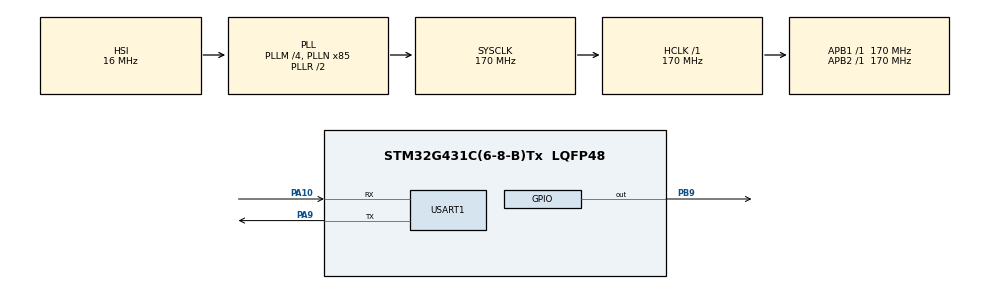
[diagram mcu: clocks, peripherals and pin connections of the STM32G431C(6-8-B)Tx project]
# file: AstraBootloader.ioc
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Mcu.Family=STM32G4
Mcu.Name=STM32G431C(6-8-B)Tx
Mcu.Package=LQFP48
NVIC.PriorityGroup=NVIC_PRIORITYGROUP_4
NVIC.USART1_IRQn=true\:2\:0\:false\:false\:true\:true\:true\:true
PA10.Mode=Asynchronous
PA10.Signal=USART1_RX
PA9.Mode=Asynchronous
PA9.Signal=USART1_TX
PB9.Signal=GPIO_Output
PC14-OSC32_IN.Mode=LSE-External-Oscillator
PC14-OSC32_IN.Signal=RCC_OSC32_IN
PC15-OSC32_OUT.Mode=LSE-External-Oscillator
PC15-OSC32_OUT.Signal=RCC_OSC32_OUT
PF0-OSC_IN.Mode=HSE-External-Oscillator
PF0-OSC_IN.Signal=RCC_OSC_IN
PF1-OSC_OUT.Mode=HSE-External-Oscillator
PF1-OSC_OUT.Signal=RCC_OSC_OUT
ProjectManager.HeapSize=0x200
ProjectManager.StackSize=0x400
ProjectManager.TargetToolchain=CMake
RCC.ADC12Freq_Value=170000000
RCC.AHBFreq_Value=170000000
RCC.APB1Freq_Value=170000000
RCC.APB1TimFreq_Value=170000000
RCC.APB2Freq_Value=170000000
RCC.APB2TimFreq_Value=170000000
RCC.CortexFreq_Value=170000000
RCC.EXTERNAL_CLOCK_VALUE=12288000
RCC.HCLKFreq_Value=170000000
RCC.HSE_VALUE=8000000
RCC.HSI48_VALUE=48000000
RCC.HSI_VALUE=16000000
RCC.PLLM=RCC_PLLM_DIV4
RCC.PLLN=85
RCC.SYSCLKFreq_VALUE=170000000
RCC.SYSCLKSource=RCC_SYSCLKSOURCE_PLLCLK
RCC.USBFreq_Value=170000000
RCC.VCOOutputFreq_Value=340000000
USART1.VirtualMode-Asynchronous=VM_ASYNC
VP_SYS_VS_DBSignals.Mode=DisableDeadBatterySignals
board=custom

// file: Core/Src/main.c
/* USER CODE BEGIN Header */
/**
  ******************************************************************************
  * @file           : main.c
  * @brief          : Main program body
  ******************************************************************************
  * @attention
  *
  * Copyright (c) 2026 STMicroelectronics.
  * All rights reserved.
  *
  * This software is licensed under terms that can be found in the LICENSE file
  * in the root directory of this software component.
  * If no LICENSE file comes with this software, it is provided AS-IS.
  *
  ******************************************************************************
  */
/* USER CODE END Header */
#include "main.h"

/* USER CODE BEGIN Includes */
#include "FlashLayout.h"
#include "stm32g4xx_hal.h"
#include "stm32g4xx_hal_gpio.h"
#include "bootloaderJump.h"
#include "AppHeader.h"
#include "OtaRequest.h"
#include "OtaStream.h"
#include "OtaEngine.h"
#include "OtaStreamUart.h"
#include "BootloaderStateMachine.h"
/* USER CODE END Includes */

/* USER CODE BEGIN PD */

/* Budget for the 20-byte header once the device has announced itself. */
#define OTA_HEADER_TIMEOUT_MS 5000U

/* Budget per stored Flash page, counted between two received chunks. */
#define OTA_PAGE_TIMEOUT_MS 5000U

/* USER CODE END PD */

UART_HandleTypeDef huart1;

/* USER CODE BEGIN PV */

static UartCtx_t otaCtx;

/* USER CODE END PV */

void SystemClock_Config(void);
static void MX_GPIO_Init(void);
static void MX_USART1_UART_Init(void);
/* USER CODE BEGIN PFP */
static void RunOtaUpdate(void);
static void OtaOnPageStored(uint32_t chunkBytes, bool isLast, void *userData);
/* USER CODE END PFP */

/* USER CODE BEGIN 0 */

static void OtaOnPageStored(uint32_t chunkBytes, bool isLast, void *userData)
{
	(void)userData;

	BootloaderSMDispatch(EVENT_DATA_PACKET_RCVD, &chunkBytes);

	if (isLast != false)
	{
		BootloaderSMDispatch(EVENT_LAST_PACKET_RCVD, NULL);
	}
}

static void RunOtaUpdate(void)
{
	OtaStream_t stream;
	AppHeader_t header;

	OtaStreamUartInit(&stream, &otaCtx, &huart1);

	if (OtaStreamUartAnnounce(&otaCtx) != 0)
	{
		BootloaderSMDispatch(EVENT_HARDWARE_ERROR, NULL);
		return;
	}

	BootloaderSMDispatch(EVENT_CONN_ESTABLISHED, NULL);

	if (OtaReadHeader(&stream, &header, OTA_HEADER_TIMEOUT_MS) != OTA_OK)
	{
		BootloaderSMDispatch(EVENT_TIMEOUT, NULL);
		return;
	}

	BootloaderSMDispatch(EVENT_SIZE_RECEIVED, &header.size);

	HAL_GPIO_WritePin(GPIOB, GPIO_PIN_9, GPIO_PIN_SET);

	if (OtaEraseAppSlot(&stream, APP_START_ADDR, header.size) != OTA_OK)
	{
		BootloaderSMDispatch(EVENT_HARDWARE_ERROR, NULL);
		return;
	}

	BootloaderSMDispatch(EVENT_ERASE_DONE, NULL);

	if (OtaReceiveImage(&stream, APP_START_ADDR, header.size, OTA_PAGE_TIMEOUT_MS,
	                    OtaOnPageStored, NULL) != OTA_OK)
	{
		BootloaderSMDispatch(EVENT_CANCEL, NULL);
		return;
	}

	if (OtaVerifyImage(&stream, APP_START_ADDR, header.size, header.crc) != OTA_OK)
	{
		BootloaderSMDispatch(EVENT_CHECKSUM_ERROR, NULL);
		return;
	}

	BootloaderSMDispatch(EVENT_CHECKSUM_OK, NULL);

	if (OtaRequestCommitHeader(&header) == false)
	{
		BootloaderSMDispatch(EVENT_HARDWARE_ERROR, NULL);
		return;
	}

	BootloaderSMDispatch(EVENT_UPDATE_SUCCESS, NULL);

	HAL_GPIO_WritePin(GPIOB, GPIO_PIN_9, GPIO_PIN_RESET);
}

/* USER CODE END 0 */

int main(void)
{

	/* MCU Configuration--------------------------------------------------------*/

	/* Reset of all peripherals, Initializes the Flash interface and the Systick. */
	HAL_Init();

	/* Configure the system clock */
	SystemClock_Config();

	/* Initialize all configured peripherals */
	MX_GPIO_Init();
	MX_USART1_UART_Init();
	/* USER CODE BEGIN 2 */

	HAL_NVIC_SetPriority(USART1_IRQn, 2, 0);
	HAL_NVIC_EnableIRQ(USART1_IRQn);
	/* USER CODE END 2 */

	/* Infinite loop */
	/* USER CODE BEGIN WHILE */
	for (uint32_t blink = 0U; blink < 3U; blink++)
	{
		HAL_GPIO_TogglePin(GPIOB, GPIO_PIN_9);
		HAL_Delay(1000);
	}

	HAL_GPIO_WritePin(GPIOB, GPIO_PIN_9, GPIO_PIN_RESET);
	BootloaderSMInit();

	if (IsOtaRequested() != false)
	{
		RunOtaUpdate();
	}
	if (IsApplicationValid() != APPLICATION_VALID)
	{
		while (1)
		{
			HAL_GPIO_TogglePin(GPIOB, GPIO_PIN_9);
			HAL_Delay(100);
		}
	}
	JumpToApplication();

	while (1)
	{
		/* USER CODE END WHILE */

	}
}

void SystemClock_Config(void)
{
	RCC_OscInitTypeDef RCC_OscInitStruct = {0};
	RCC_ClkInitTypeDef RCC_ClkInitStruct = {0};

	/** Configure the main internal regulator output voltage
  */
	HAL_PWREx_ControlVoltageScaling(PWR_REGULATOR_VOLTAGE_SCALE1_BOOST);

	/** Initializes the RCC Oscillators according to the specified parameters
  * in the RCC_OscInitTypeDef structure.
  */
	RCC_OscInitStruct.OscillatorType = RCC_OSCILLATORTYPE_HSI;
	RCC_OscInitStruct.HSIState = RCC_HSI_ON;
	RCC_OscInitStruct.HSICalibrationValue = RCC_HSICALIBRATION_DEFAULT;
	RCC_OscInitStruct.PLL.PLLState = RCC_PLL_ON;
	RCC_OscInitStruct.PLL.PLLSource = RCC_PLLSOURCE_HSI;
	RCC_OscInitStruct.PLL.PLLM = RCC_PLLM_DIV4;
	RCC_OscInitStruct.PLL.PLLN = 85;
	RCC_OscInitStruct.PLL.PLLP = RCC_PLLP_DIV2;
	RCC_OscInitStruct.PLL.PLLQ = RCC_PLLQ_DIV2;
	RCC_OscInitStruct.PLL.PLLR = RCC_PLLR_DIV2;
	if (HAL_RCC_OscConfig(&RCC_OscInitStruct) != HAL_OK)
	{
		Error_Handler();
	}

	/** Initializes the CPU, AHB and APB buses clocks
  */
	RCC_ClkInitStruct.ClockType = RCC_CLOCKTYPE_HCLK | RCC_CLOCKTYPE_SYSCLK |
	                              RCC_CLOCKTYPE_PCLK1 | RCC_CLOCKTYPE_PCLK2;
	RCC_ClkInitStruct.SYSCLKSource = RCC_SYSCLKSOURCE_PLLCLK;
	RCC_ClkInitStruct.AHBCLKDivider = RCC_SYSCLK_DIV1;
	RCC_ClkInitStruct.APB1CLKDivider = RCC_HCLK_DIV1;
	RCC_ClkInitStruct.APB2CLKDivider = RCC_HCLK_DIV1;

	if (HAL_RCC_ClockConfig(&RCC_ClkInitStruct, FLASH_LATENCY_4) != HAL_OK)
	{
		Error_Handler();
	}
}

static void MX_USART1_UART_Init(void)
{

	huart1.Instance = USART1;
	huart1.Init.BaudRate = 115200;
	huart1.Init.WordLength = UART_WORDLENGTH_8B;
	huart1.Init.StopBits = UART_STOPBITS_1;
	huart1.Init.Parity = UART_PARITY_NONE;
	huart1.Init.Mode = UART_MODE_TX_RX;
	huart1.Init.HwFlowCtl = UART_HWCONTROL_NONE;
	huart1.Init.OverSampling = UART_OVERSAMPLING_16;
	huart1.Init.OneBitSampling = UART_ONE_BIT_SAMPLE_DISABLE;
	huart1.Init.ClockPrescaler = UART_PRESCALER_DIV1;
	huart1.AdvancedInit.AdvFeatureInit = UART_ADVFEATURE_NO_INIT;
	if (HAL_UART_Init(&huart1) != HAL_OK)
	{
		Error_Handler();
	}
	if (HAL_UARTEx_SetTxFifoThreshold(&huart1, UART_TXFIFO_THRESHOLD_1_8) !=
	    HAL_OK)
	{
		Error_Handler();
	}
	if (HAL_UARTEx_SetRxFifoThreshold(&huart1, UART_RXFIFO_THRESHOLD_1_8) !=
	    HAL_OK)
	{
		Error_Handler();
	}
	if (HAL_UARTEx_DisableFifoMode(&huart1) != HAL_OK)
	{
		Error_Handler();
	}
}

static void MX_GPIO_Init(void)
{
	GPIO_InitTypeDef GPIO_InitStruct = {0};

	/* GPIO Ports Clock Enable */
	__HAL_RCC_GPIOC_CLK_ENABLE();
	__HAL_RCC_GPIOF_CLK_ENABLE();
	__HAL_RCC_GPIOA_CLK_ENABLE();
	__HAL_RCC_GPIOB_CLK_ENABLE();

	/*Configure GPIO pin Output Level */
	HAL_GPIO_WritePin(GPIOB, GPIO_PIN_9, GPIO_PIN_RESET);

	/*Configure GPIO pin : BOOTLOADER_STATUS_LED_Pin */
	GPIO_InitStruct.Pin = GPIO_PIN_9;
	GPIO_InitStruct.Mode = GPIO_MODE_OUTPUT_PP;
	GPIO_InitStruct.Pull = GPIO_NOPULL;
	GPIO_InitStruct.Speed = GPIO_SPEED_FREQ_LOW;
	HAL_GPIO_Init(GPIOB, &GPIO_InitStruct);

}

void Error_Handler(void)
{
	__disable_irq();
	while (1)
	{
	}
}
